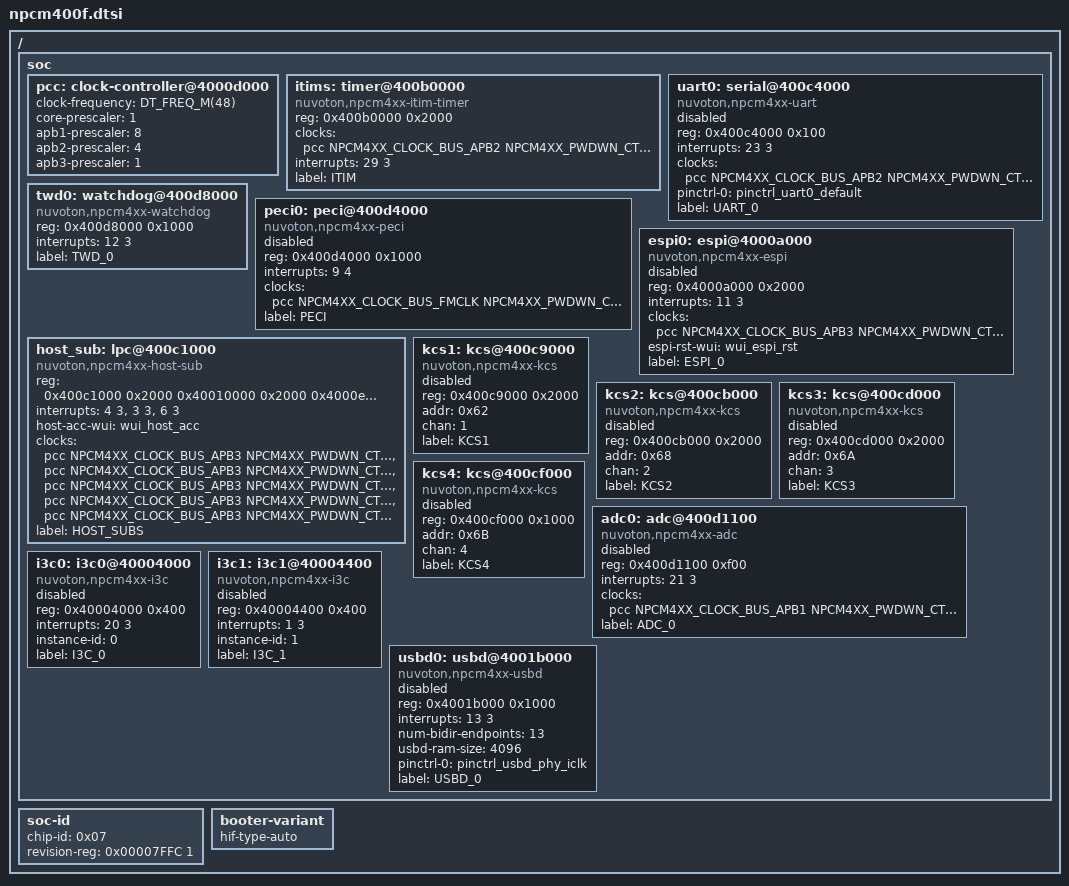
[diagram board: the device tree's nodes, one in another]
/*
 * Copyright (c) 2021 Nuvoton Technology Corporation.
 *
 * SPDX-License-Identifier: Apache-2.0
 */


/* Device tree declarations of npcm4xx soc family */
#include "npcm4xx.dtsi"
#include "npcm4xx/npcm4xx-pinctrl.dtsi"

/ {
	soc {

		pcc: clock-controller@4000d000 {
			clock-frequency = <DT_FREQ_M(48)>; /* OFMCLK runs at 48MHz */
			core-prescaler = <1>; /* CORE_CLK runs at 48MHz */
			apb1-prescaler = <8>; /* APB1_CLK runs at 6MHz */
			apb2-prescaler = <4>; /* APB2_CLK runs at 12MHz */
			apb3-prescaler = <1>; /* APB3_CLK runs at 48MHz */
		};

		/* Specific soc devices in npcm400f series */
		itims: timer@400b0000 {
			compatible = "nuvoton,npcm4xx-itim-timer";
			reg = <0x400b0000 0x2000>;
			reg-names = "itim1";
			clocks = <&pcc NPCM4XX_CLOCK_BUS_APB2 NPCM4XX_PWDWN_CTL4 0>;
			interrupts = <29 3>;
			label = "ITIM";
		};

		uart0: serial@400c4000 {
			compatible = "nuvoton,npcm4xx-uart";
			reg = <0x400c4000 0x100>;
			interrupts = <23 3>;
			clocks = <&pcc NPCM4XX_CLOCK_BUS_APB2 NPCM4XX_PWDWN_CTL1 4>;
			pinctrl-0 = <&pinctrl_uart0_default>;
			/* uart-rx = <&wui_cr_sin1>;*/
			status = "disabled";
			label = "UART_0";
		};

		twd0: watchdog@400d8000 {
			compatible = "nuvoton,npcm4xx-watchdog";
			reg = <0x400d8000 0x1000>;
			interrupts = <12 3>;
			label = "TWD_0";
		};

		peci0: peci@400d4000 {
			compatible = "nuvoton,npcm4xx-peci";
			reg = <0x400d4000 0x1000>;
			#address-cells = <1>;
			#size-cells = <0>;
			interrupts = <9 4>;
			clocks = <&pcc NPCM4XX_CLOCK_BUS_FMCLK NPCM4XX_PWDWN_CTL4 5>;
			label = "PECI";
			status = "disabled";
		};

		espi0: espi@4000a000 {
			compatible = "nuvoton,npcm4xx-espi";
			reg = <0x4000a000 0x2000>;
			interrupts = <11 3>; /* Interrupt for eSPI Bus */
			/* clocks for eSPI modules */
			clocks = <&pcc NPCM4XX_CLOCK_BUS_APB3 NPCM4XX_PWDWN_CTL6 7>;
			/* WUI maps for eSPI signals */
			espi-rst-wui = <&wui_espi_rst>;
			label = "ESPI_0";
			#address-cells = <1>;
			#size-cells = <0>;
			#vw-cells = <3>;
			status = "disabled";
		};

		host_sub: lpc@400c1000 {
			compatible = "nuvoton,npcm4xx-host-sub";
			/* host sub-module register address & size */
			reg = <0x400c1000 0x2000
			       0x40010000 0x2000
			       0x4000e000 0x2000
			       0x400c9000 0x2000
			       0x400cb000 0x2000
			       0x400cd000 0x2000
			       0x400cf000 0x1000>;
			reg-names = "mswc", "shm", "c2h", "pm_acpi",
				    "pm_hcmd", "pmch3", "pmch4";

			/* host sub-module IRQ and priority */
			interrupts = <4 3>, /* PMCH Input-Buf-Full (IBF) */
				     <3 3>,  /* PMCH Output-Buf-Empty (OBE) */
				     <6 3>;  /* Port80 FIFO Not Empty */
			interrupt-names = "pmch_ibf", "pmch_obe", "p80_fifo";

			/* WUI map for accessing host sub-modules */
			host-acc-wui = <&wui_host_acc>;

			/* clocks for host sub-modules */
			clocks = <&pcc NPCM4XX_CLOCK_BUS_APB3 NPCM4XX_PWDWN_CTL5 3>,
				 <&pcc NPCM4XX_CLOCK_BUS_APB3 NPCM4XX_PWDWN_CTL5 4>,
				 <&pcc NPCM4XX_CLOCK_BUS_APB3 NPCM4XX_PWDWN_CTL5 5>,
				 <&pcc NPCM4XX_CLOCK_BUS_APB3 NPCM4XX_PWDWN_CTL5 6>,
				 <&pcc NPCM4XX_CLOCK_BUS_APB3 NPCM4XX_PWDWN_CTL5 7>;
			label = "HOST_SUBS";
		};

		kcs1: kcs@400c9000 {
			compatible = "nuvoton,npcm4xx-kcs";
			/* KCS1/PMCH1 register address & size */
			reg = <0x400c9000 0x2000>;
			reg-names = "kcs1";
			addr = <0x62>;
			chan = <1>;
			label = "KCS1";
			status = "disabled";
		};

		kcs2: kcs@400cb000 {
			compatible = "nuvoton,npcm4xx-kcs";
			/* KCS1/PMCH1 register address & size */
			reg = <0x400cb000 0x2000>;
			reg-names = "kcs2";
			addr = <0x68>;
			chan = <2>;
			label = "KCS2";
			status = "disabled";
		};

		kcs3: kcs@400cd000 {
			compatible = "nuvoton,npcm4xx-kcs";
			/* KCS1/PMCH1 register address & size */
			reg = <0x400cd000 0x2000>;
			reg-names = "kcs3";
			addr = <0x6A>;
			chan = <3>;
			label = "KCS3";
			status = "disabled";
		};

		kcs4: kcs@400cf000 {
			compatible = "nuvoton,npcm4xx-kcs";
			/* KCS1/PMCH1 register address & size */
			reg = <0x400cf000 0x1000>;
			reg-names = "kcs4";
			addr = <0x6B>;
			chan = <4>;
			label = "KCS4";
			status = "disabled";
		};

		adc0: adc@400d1100 {
			compatible = "nuvoton,npcm4xx-adc";
			#io-channel-cells = <1>;
			reg = <0x400d1100 0xf00>;
			interrupts = <21 3>;
			clocks = <&pcc NPCM4XX_CLOCK_BUS_APB1 NPCM4XX_PWDWN_CTL4 4>;
			status = "disabled";
			label = "ADC_0";
		};

		i3c0: i3c0@40004000 {
			compatible = "nuvoton,npcm4xx-i3c";
			#address-cells = <1>;
			#size-cells = <0>;
			reg = <0x40004000 0x400>;
			interrupts = <20 3>;
			instance-id = <0>;
			status = "disabled";
			label = "I3C_0";
		};

		i3c1: i3c1@40004400 {
			compatible = "nuvoton,npcm4xx-i3c";
			#address-cells = <1>;
			#size-cells = <0>;
			reg = <0x40004400 0x400>;
			interrupts = <1 3>;
			instance-id = <1>;
			status = "disabled";
			label = "I3C_1";
		};

		usbd0: usbd@4001b000 {
			compatible = "nuvoton,npcm4xx-usbd";
			reg = <0x4001b000 0x1000>;
			interrupts = <13 3>;
			num-bidir-endpoints = <13>;
			usbd-ram-size = <4096>;
			pinctrl-0 = <&pinctrl_usbd_phy_iclk>;
			/* pinctrl-0 = <&pinctrl_usbd_phy_xclk>; */
			label = "USBD_0";
			status = "disabled";
		};

		usbd0: usbd@4001b000 {
			compatible = "nuvoton,npcm4xx-usbd";
			reg = <0x4001b000 0x1000>;
			interrupts = <13 3>;
			num-bidir-endpoints = <13>;
			usbd-ram-size = <4096>;
			pinctrl-0 = <&pinctrl_usbd_phy_iclk>;
			/* pinctrl-0 = <&pinctrl_usbd_phy_xclk>; */
			label = "USBD_0";
			status = "disabled";
		};
	};

	soc-id {
		chip-id = <0x07>;
		revision-reg = <0x00007FFC 1>;
	};

	booter-variant {
		hif-type-auto;
	};
};
